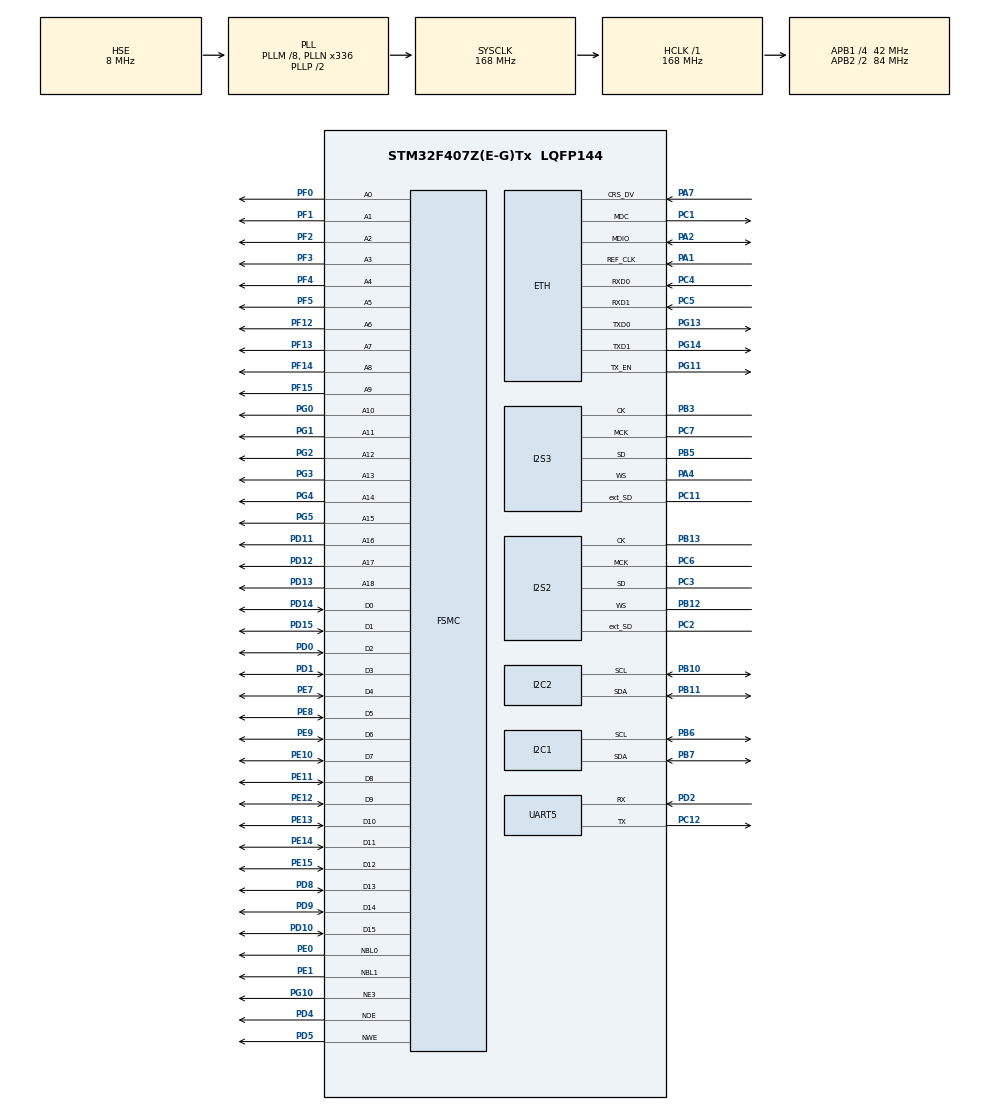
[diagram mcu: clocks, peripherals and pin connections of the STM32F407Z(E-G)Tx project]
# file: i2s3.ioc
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Dma.Request0=SPI3_TX
Dma.Request1=SPI2_TX
Dma.SPI2_TX.1.Direction=DMA_MEMORY_TO_PERIPH
Dma.SPI2_TX.1.FIFOMode=DMA_FIFOMODE_ENABLE
Dma.SPI2_TX.1.FIFOThreshold=DMA_FIFO_THRESHOLD_FULL
Dma.SPI2_TX.1.Instance=DMA1_Stream4
Dma.SPI2_TX.1.MemBurst=DMA_MBURST_SINGLE
Dma.SPI2_TX.1.MemDataAlignment=DMA_MDATAALIGN_HALFWORD
Dma.SPI2_TX.1.MemInc=DMA_MINC_ENABLE
Dma.SPI2_TX.1.Mode=DMA_NORMAL
Dma.SPI2_TX.1.PeriphBurst=DMA_PBURST_SINGLE
Dma.SPI2_TX.1.PeriphDataAlignment=DMA_PDATAALIGN_HALFWORD
Dma.SPI2_TX.1.PeriphInc=DMA_PINC_DISABLE
Dma.SPI2_TX.1.Priority=DMA_PRIORITY_LOW
Dma.SPI3_TX.0.Direction=DMA_MEMORY_TO_PERIPH
Dma.SPI3_TX.0.FIFOMode=DMA_FIFOMODE_ENABLE
Dma.SPI3_TX.0.FIFOThreshold=DMA_FIFO_THRESHOLD_FULL
Dma.SPI3_TX.0.Instance=DMA1_Stream5
Dma.SPI3_TX.0.MemBurst=DMA_MBURST_SINGLE
Dma.SPI3_TX.0.MemDataAlignment=DMA_MDATAALIGN_HALFWORD
Dma.SPI3_TX.0.MemInc=DMA_MINC_ENABLE
Dma.SPI3_TX.0.Mode=DMA_NORMAL
Dma.SPI3_TX.0.PeriphBurst=DMA_PBURST_SINGLE
Dma.SPI3_TX.0.PeriphDataAlignment=DMA_PDATAALIGN_HALFWORD
Dma.SPI3_TX.0.PeriphInc=DMA_PINC_DISABLE
Dma.SPI3_TX.0.Priority=DMA_PRIORITY_LOW
ETH.MediaInterface=ETH_MEDIA_INTERFACE_RMII
ETH.PHY_Name_RMII=DP83848_PHY_ADDRESS
FSMC.AddressSetupTime3=2
FSMC.BusTurnAroundDuration3=0
FSMC.DataSetupTime3=7
FSMC.WriteOperation3=FSMC_WRITE_OPERATION_ENABLE
I2S2.AudioFreq=I2S_AUDIOFREQ_16K
I2S2.ErrorAudioFreq=1.9 %
I2S2.FullDuplexMode=I2S_FULLDUPLEXMODE_ENABLE
I2S2.Instance=SPI$Index
I2S2.RealAudioFreq=16.304 KHz
I2S2.VirtualMode=I2S_MODE_MASTER
I2S3.AudioFreq=I2S_AUDIOFREQ_16K
I2S3.ErrorAudioFreq=1.9 %
I2S3.FullDuplexMode=I2S_FULLDUPLEXMODE_ENABLE
I2S3.Instance=SPI$Index
I2S3.RealAudioFreq=16.304 KHz
I2S3.VirtualMode=I2S_MODE_MASTER
LWIP.GATEWAY_ADDRESS=192.168.001.001
LWIP.IP_ADDRESS=192.168.001.200
LWIP.LWIP_DHCP=0
LWIP.MEMP_NUM_TCP_SEG=1000
LWIP.MEM_SIZE=970*15
LWIP.NETMASK_ADDRESS=255.255.255.000
LWIP.PBUF_POOL_BUFSIZE=970
LWIP.TCP_MSS=970
LWIP.TCP_SND_BUF=4850
LWIP.TCP_SND_QUEUELEN=1000
LWIP.TCP_WND=4850
LWIP.Version=v2.1.2_Cube
Mcu.Family=STM32F4
Mcu.Name=STM32F407Z(E-G)Tx
Mcu.Package=LQFP144
NVIC.DMA1_Stream4_IRQn=true\:2\:0\:true\:false\:true\:false\:true
NVIC.DMA1_Stream5_IRQn=true\:6\:0\:true\:false\:true\:false\:true
NVIC.ETH_IRQn=true\:2\:0\:true\:false\:true\:true\:true
NVIC.PriorityGroup=NVIC_PRIORITYGROUP_4
PA1.Mode=RMII
PA1.Signal=ETH_REF_CLK
PA2.Mode=RMII
PA2.Signal=ETH_MDIO
PA4.Mode=Full_Duplex_Master
PA4.Signal=I2S3_WS
PA7.Mode=RMII
PA7.Signal=ETH_CRS_DV
PB10.GPIO_Pu=GPIO_PULLUP
PB10.Mode=I2C
PB10.Signal=I2C2_SCL
PB11.GPIO_Pu=GPIO_PULLUP
PB11.Mode=I2C
PB11.Signal=I2C2_SDA
PB12.Mode=Full_Duplex_Master
PB12.Signal=I2S2_WS
PB13.Mode=Full_Duplex_Master
PB13.Signal=I2S2_CK
PB3.Mode=Full_Duplex_Master
PB3.Signal=I2S3_CK
PB5.Mode=Full_Duplex_Master
PB5.Signal=I2S3_SD
PB6.GPIO_Pu=GPIO_PULLUP
PB6.Mode=I2C
PB6.Signal=I2C1_SCL
PB7.GPIO_Pu=GPIO_PULLUP
PB7.Mode=I2C
PB7.Signal=I2C1_SDA
PC1.Mode=RMII
PC1.Signal=ETH_MDC
PC11.Mode=Full_Duplex_Master
PC11.Signal=I2S3_ext_SD
PC12.Mode=Asynchronous
PC12.Signal=UART5_TX
PC2.Mode=Full_Duplex_Master
PC2.Signal=I2S2_ext_SD
PC3.Mode=Full_Duplex_Master
PC3.Signal=I2S2_SD
PC4.Mode=RMII
PC4.Signal=ETH_RXD0
PC5.Mode=RMII
PC5.Signal=ETH_RXD1
PC6.Mode=Master_Clock_Activated
PC6.Signal=I2S2_MCK
PC7.Mode=Master_Clock_Activated
PC7.Signal=I2S3_MCK
PD0.Signal=FSMC_D2_DA2
PD1.Signal=FSMC_D3_DA3
PD10.Signal=FSMC_D15_DA15
PD11.Signal=FSMC_A16_CLE
PD12.Signal=FSMC_A17_ALE
PD13.Signal=FSMC_A18
PD14.Signal=FSMC_D0_DA0
PD15.Signal=FSMC_D1_DA1
PD2.Mode=Asynchronous
PD2.Signal=UART5_RX
PD4.Signal=FSMC_NOE
PD5.Signal=FSMC_NWE
PD8.Signal=FSMC_D13_DA13
PD9.Signal=FSMC_D14_DA14
PE0.Signal=FSMC_NBL0
PE1.Signal=FSMC_NBL1
PE10.Signal=FSMC_D7_DA7
PE11.Signal=FSMC_D8_DA8
PE12.Signal=FSMC_D9_DA9
PE13.Signal=FSMC_D10_DA10
PE14.Signal=FSMC_D11_DA11
PE15.Signal=FSMC_D12_DA12
PE7.Signal=FSMC_D4_DA4
PE8.Signal=FSMC_D5_DA5
PE9.Signal=FSMC_D6_DA6
PF0.Signal=FSMC_A0
PF1.Signal=FSMC_A1
PF12.Signal=FSMC_A6
PF13.Signal=FSMC_A7
PF14.Signal=FSMC_A8
PF15.Signal=FSMC_A9
PF2.Signal=FSMC_A2
PF3.Signal=FSMC_A3
PF4.Signal=FSMC_A4
PF5.Signal=FSMC_A5
PG0.Signal=FSMC_A10
PG1.Signal=FSMC_A11
PG10.Mode=NorPsramChipSelect3_3
PG10.Signal=FSMC_NE3
PG11.Mode=RMII
PG11.Signal=ETH_TX_EN
PG13.Mode=RMII
PG13.Signal=ETH_TXD0
PG14.Mode=RMII
PG14.Signal=ETH_TXD1
PG2.Signal=FSMC_A12
PG3.Signal=FSMC_A13
PG4.Signal=FSMC_A14
PG5.Signal=FSMC_A15
PH0-OSC_IN.Mode=HSE-External-Oscillator
PH0-OSC_IN.Signal=RCC_OSC_IN
PH1-OSC_OUT.Mode=HSE-External-Oscillator
PH1-OSC_OUT.Signal=RCC_OSC_OUT
ProjectManager.HeapSize=0x800
ProjectManager.StackSize=0x800
ProjectManager.TargetToolchain=STM32CubeIDE
RCC.48MHZClocksFreq_Value=48000000
RCC.AHBFreq_Value=168000000
RCC.APB1CLKDivider=RCC_HCLK_DIV4
RCC.APB1Freq_Value=42000000
RCC.APB1TimFreq_Value=84000000
RCC.APB2CLKDivider=RCC_HCLK_DIV2
RCC.APB2Freq_Value=84000000
RCC.APB2TimFreq_Value=168000000
RCC.CortexFreq_Value=168000000
RCC.HCLKFreq_Value=168000000
RCC.HSE_VALUE=8000000
RCC.HSI_VALUE=16000000
RCC.LSE_VALUE=32768
RCC.PLLM=8
RCC.PLLN=336
RCC.PLLQ=7
RCC.PLLSourceVirtual=RCC_PLLSOURCE_HSE
RCC.SYSCLKFreq_VALUE=168000000
RCC.SYSCLKSource=RCC_SYSCLKSOURCE_PLLCLK
RCC.VCOOutputFreq_Value=336000000
SH.FSMC_A0.0=FSMC_A0,19b-a3
SH.FSMC_A1.0=FSMC_A1,19b-a3
SH.FSMC_A10.0=FSMC_A10,19b-a3
SH.FSMC_A11.0=FSMC_A11,19b-a3
SH.FSMC_A12.0=FSMC_A12,19b-a3
SH.FSMC_A13.0=FSMC_A13,19b-a3
SH.FSMC_A14.0=FSMC_A14,19b-a3
SH.FSMC_A15.0=FSMC_A15,19b-a3
SH.FSMC_A16_CLE.0=FSMC_A16,19b-a3
SH.FSMC_A17_ALE.0=FSMC_A17,19b-a3
SH.FSMC_A18.0=FSMC_A18,19b-a3
SH.FSMC_A2.0=FSMC_A2,19b-a3
SH.FSMC_A3.0=FSMC_A3,19b-a3
SH.FSMC_A4.0=FSMC_A4,19b-a3
SH.FSMC_A5.0=FSMC_A5,19b-a3
SH.FSMC_A6.0=FSMC_A6,19b-a3
SH.FSMC_A7.0=FSMC_A7,19b-a3
SH.FSMC_A8.0=FSMC_A8,19b-a3
SH.FSMC_A9.0=FSMC_A9,19b-a3
SH.FSMC_D0_DA0.0=FSMC_D0,16b-d3
SH.FSMC_D10_DA10.0=FSMC_D10,16b-d3
SH.FSMC_D11_DA11.0=FSMC_D11,16b-d3
SH.FSMC_D12_DA12.0=FSMC_D12,16b-d3
SH.FSMC_D13_DA13.0=FSMC_D13,16b-d3
SH.FSMC_D14_DA14.0=FSMC_D14,16b-d3
SH.FSMC_D15_DA15.0=FSMC_D15,16b-d3
SH.FSMC_D1_DA1.0=FSMC_D1,16b-d3
SH.FSMC_D2_DA2.0=FSMC_D2,16b-d3
SH.FSMC_D3_DA3.0=FSMC_D3,16b-d3
SH.FSMC_D4_DA4.0=FSMC_D4,16b-d3
SH.FSMC_D5_DA5.0=FSMC_D5,16b-d3
SH.FSMC_D6_DA6.0=FSMC_D6,16b-d3
SH.FSMC_D7_DA7.0=FSMC_D7,16b-d3
SH.FSMC_D8_DA8.0=FSMC_D8,16b-d3
SH.FSMC_D9_DA9.0=FSMC_D9,16b-d3
SH.FSMC_NBL0.0=FSMC_NBL0,2ByteEnable3
SH.FSMC_NBL1.0=FSMC_NBL1,2ByteEnable3
SH.FSMC_NOE.0=FSMC_NOE,Sram3
SH.FSMC_NWE.0=FSMC_NWE,Sram3
UART5.VirtualMode=Asynchronous
VP_LWIP_VS_Enabled.Mode=Enabled
board=custom

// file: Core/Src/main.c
/* USER CODE BEGIN Header */
/**
  ******************************************************************************
  * @file           : main.c
  * @brief          : Main program body
  ******************************************************************************
  * @attention
  *
  * Copyright (c) 2025 STMicroelectronics.
  * All rights reserved.
  *
  * This software is licensed under terms that can be found in the LICENSE file
  * in the root directory of this software component.
  * If no LICENSE file comes with this software, it is provided AS-IS.
  *
  ******************************************************************************
  */
/* USER CODE END Header */
#include "main.h"
#include "lwip.h"

/* USER CODE BEGIN Includes */
#include "audio_player.h"
#include "tcpClientRAW.h"
#include "i2s.h"
/* USER CODE END Includes */

I2C_HandleTypeDef hi2c1;
I2C_HandleTypeDef hi2c2;

I2S_HandleTypeDef hi2s2;
I2S_HandleTypeDef hi2s3;
DMA_HandleTypeDef hdma_spi2_tx;
DMA_HandleTypeDef hdma_spi3_tx;

UART_HandleTypeDef huart5;

SRAM_HandleTypeDef hsram3;

void SystemClock_Config(void);
void PeriphCommonClock_Config(void);
static void MX_GPIO_Init(void);
static void MX_DMA_Init(void);
static void MX_I2S3_Init(void);
static void MX_I2C1_Init(void);
static void MX_I2C2_Init(void);
static void MX_I2S2_Init(void);
static void MX_UART5_Init(void);
static void MX_FSMC_Init(void);
/* USER CODE BEGIN PFP */
#define BUFFSIZE  970
/* USER CODE END PFP */

/* USER CODE BEGIN 0 */
#include <string.h>
#include <stdio.h>

#ifdef __GNUC__
  /* With GCC, small printf (option LD Linker->Libraries->Small printf
     set to 'Yes') calls __io_putchar() */
int __io_putchar(int ch)
#else
int fputc(int ch, FILE *f)
#endif /* __GNUC__ */
{
  /* Place your implementation of fputc here */
  /* e.g. write a character to the UART3 and Loop until the end of transmission */
  HAL_UART_Transmit(&huart5, (uint8_t *)&ch, 1, HAL_MAX_DELAY);
  return ch;
}

char      UsbDiskPath[4] = {0};                         /* USB Host logical drive path */
uint32_t  byteswritten, bytesread;                      /* File write/read counts */
char      file_name[] = "recorder.wav";                     /* File name */
char      file_name2[] = "queen.wav";                     /* File name */

uint8_t wavsram[11640];
//uint8_t wavsram[1024000] __attribute__((section(".sram")));

//extern uint8_t wavsram[1024000];

/* USER CODE END 0 */

int main(void)
{

  /* MCU Configuration--------------------------------------------------------*/

  /* Reset of all peripherals, Initializes the Flash interface and the Systick. */
  HAL_Init();

  /* Configure the system clock */
  SystemClock_Config();

/* Configure the peripherals common clocks */
  PeriphCommonClock_Config();

  /* Initialize all configured peripherals */
  MX_GPIO_Init();
  MX_DMA_Init();
  MX_I2S3_Init();
  MX_I2C1_Init();
  MX_I2C2_Init();
  MX_I2S2_Init();
  MX_UART5_Init();
  MX_LWIP_Init();
  MX_FSMC_Init();
  /* USER CODE BEGIN 2 */
  Audio_Player_Init(&hi2c2);

  Audio_Player_Init(&hi2c1);
  	HAL_Delay(1000);
	WM8978_HPvol_Set(40, 40);	//耳机音量设置
	WM8978_SPKvol_Set(50);	//喇叭音量设置
  	WM8978_ADDA_Cfg(0, 1);		//�????????????????????????????????????????启ADC
  	WM8978_Input_Cfg(1, 1, 0);	//�????????????????????????????????????????启输入�?�道(MIC&LINE IN)
  	WM8978_Output_Cfg(0, 1);		//�????????????????????????????????????????启BYPASS输出
  	WM8978_MIC_Gain(46);		//MIC增益设置
  	WM8978_I2S_Cfg(2, 0);//
  //ETX_MSC_ProcessUsbDevice();

//  res = f_mount( &UsbDiskFatFs, (TCHAR const*)UsbDiskPath, 0 );
//  printf("mount %d\n",res);
//  res = f_open( &file, file_name, FA_READ );
//  f_lseek(&file,44);
//  printf("open %d\n",res);
//  res = f_open( &file2, file_name2, FA_READ );
//  f_lseek(&file2,44);
//  printf("open %d\n",res);
  tcp_client_init();
  //Audio_Player_Start();

  /* USER CODE END 2 */

  /* Infinite loop */
  while (1)
  {

    /* USER CODE BEGIN 3 */
	  MX_LWIP_Process();

	 // HAL_Delay(50000);
  }
  /* USER CODE END 3 */
}

void SystemClock_Config(void)
{
  RCC_OscInitTypeDef RCC_OscInitStruct = {0};
  RCC_ClkInitTypeDef RCC_ClkInitStruct = {0};

  /** Configure the main internal regulator output voltage
  */
  __HAL_RCC_PWR_CLK_ENABLE();
  __HAL_PWR_VOLTAGESCALING_CONFIG(PWR_REGULATOR_VOLTAGE_SCALE1);
  /** Initializes the RCC Oscillators according to the specified parameters
  * in the RCC_OscInitTypeDef structure.
  */
  RCC_OscInitStruct.OscillatorType = RCC_OSCILLATORTYPE_HSE;
  RCC_OscInitStruct.HSEState = RCC_HSE_ON;
  RCC_OscInitStruct.PLL.PLLState = RCC_PLL_ON;
  RCC_OscInitStruct.PLL.PLLSource = RCC_PLLSOURCE_HSE;
  RCC_OscInitStruct.PLL.PLLM = 8;
  RCC_OscInitStruct.PLL.PLLN = 336;
  RCC_OscInitStruct.PLL.PLLP = RCC_PLLP_DIV2;
  RCC_OscInitStruct.PLL.PLLQ = 7;
  if (HAL_RCC_OscConfig(&RCC_OscInitStruct) != HAL_OK)
  {
    Error_Handler();
  }
  /** Initializes the CPU, AHB and APB buses clocks
  */
  RCC_ClkInitStruct.ClockType = RCC_CLOCKTYPE_HCLK|RCC_CLOCKTYPE_SYSCLK
                              |RCC_CLOCKTYPE_PCLK1|RCC_CLOCKTYPE_PCLK2;
  RCC_ClkInitStruct.SYSCLKSource = RCC_SYSCLKSOURCE_PLLCLK;
  RCC_ClkInitStruct.AHBCLKDivider = RCC_SYSCLK_DIV1;
  RCC_ClkInitStruct.APB1CLKDivider = RCC_HCLK_DIV4;
  RCC_ClkInitStruct.APB2CLKDivider = RCC_HCLK_DIV2;

  if (HAL_RCC_ClockConfig(&RCC_ClkInitStruct, FLASH_LATENCY_5) != HAL_OK)
  {
    Error_Handler();
  }
}

void PeriphCommonClock_Config(void)
{
  RCC_PeriphCLKInitTypeDef PeriphClkInitStruct = {0};

  /** Initializes the peripherals clock
  */
  PeriphClkInitStruct.PeriphClockSelection = RCC_PERIPHCLK_I2S;
  PeriphClkInitStruct.PLLI2S.PLLI2SN = 192;
  PeriphClkInitStruct.PLLI2S.PLLI2SR = 2;
  if (HAL_RCCEx_PeriphCLKConfig(&PeriphClkInitStruct) != HAL_OK)
  {
    Error_Handler();
  }
}

static void MX_I2C1_Init(void)
{

  hi2c1.Instance = I2C1;
  hi2c1.Init.ClockSpeed = 100000;
  hi2c1.Init.DutyCycle = I2C_DUTYCYCLE_2;
  hi2c1.Init.OwnAddress1 = 0;
  hi2c1.Init.AddressingMode = I2C_ADDRESSINGMODE_7BIT;
  hi2c1.Init.DualAddressMode = I2C_DUALADDRESS_DISABLE;
  hi2c1.Init.OwnAddress2 = 0;
  hi2c1.Init.GeneralCallMode = I2C_GENERALCALL_DISABLE;
  hi2c1.Init.NoStretchMode = I2C_NOSTRETCH_DISABLE;
  if (HAL_I2C_Init(&hi2c1) != HAL_OK)
  {
    Error_Handler();
  }

}

static void MX_I2C2_Init(void)
{

  hi2c2.Instance = I2C2;
  hi2c2.Init.ClockSpeed = 100000;
  hi2c2.Init.DutyCycle = I2C_DUTYCYCLE_2;
  hi2c2.Init.OwnAddress1 = 0;
  hi2c2.Init.AddressingMode = I2C_ADDRESSINGMODE_7BIT;
  hi2c2.Init.DualAddressMode = I2C_DUALADDRESS_DISABLE;
  hi2c2.Init.OwnAddress2 = 0;
  hi2c2.Init.GeneralCallMode = I2C_GENERALCALL_DISABLE;
  hi2c2.Init.NoStretchMode = I2C_NOSTRETCH_DISABLE;
  if (HAL_I2C_Init(&hi2c2) != HAL_OK)
  {
    Error_Handler();
  }

}

static void MX_I2S2_Init(void)
{

  hi2s2.Instance = SPI2;
  hi2s2.Init.Mode = I2S_MODE_MASTER_TX;
  hi2s2.Init.Standard = I2S_STANDARD_PHILIPS;
  hi2s2.Init.DataFormat = I2S_DATAFORMAT_16B;
  hi2s2.Init.MCLKOutput = I2S_MCLKOUTPUT_ENABLE;
  hi2s2.Init.AudioFreq = I2S_AUDIOFREQ_16K;
  hi2s2.Init.CPOL = I2S_CPOL_LOW;
  hi2s2.Init.ClockSource = I2S_CLOCK_PLL;
  hi2s2.Init.FullDuplexMode = I2S_FULLDUPLEXMODE_ENABLE;
  if (HAL_I2S_Init(&hi2s2) != HAL_OK)
  {
    Error_Handler();
  }

}

static void MX_I2S3_Init(void)
{

  hi2s3.Instance = SPI3;
  hi2s3.Init.Mode = I2S_MODE_MASTER_TX;
  hi2s3.Init.Standard = I2S_STANDARD_PHILIPS;
  hi2s3.Init.DataFormat = I2S_DATAFORMAT_16B;
  hi2s3.Init.MCLKOutput = I2S_MCLKOUTPUT_ENABLE;
  hi2s3.Init.AudioFreq = I2S_AUDIOFREQ_16K;
  hi2s3.Init.CPOL = I2S_CPOL_LOW;
  hi2s3.Init.ClockSource = I2S_CLOCK_PLL;
  hi2s3.Init.FullDuplexMode = I2S_FULLDUPLEXMODE_ENABLE;
  if (HAL_I2S_Init(&hi2s3) != HAL_OK)
  {
    Error_Handler();
  }

}

static void MX_UART5_Init(void)
{

  huart5.Instance = UART5;
  huart5.Init.BaudRate = 115200;
  huart5.Init.WordLength = UART_WORDLENGTH_8B;
  huart5.Init.StopBits = UART_STOPBITS_1;
  huart5.Init.Parity = UART_PARITY_NONE;
  huart5.Init.Mode = UART_MODE_TX_RX;
  huart5.Init.HwFlowCtl = UART_HWCONTROL_NONE;
  huart5.Init.OverSampling = UART_OVERSAMPLING_16;
  if (HAL_UART_Init(&huart5) != HAL_OK)
  {
    Error_Handler();
  }

}

static void MX_DMA_Init(void)
{

  /* DMA controller clock enable */
  __HAL_RCC_DMA1_CLK_ENABLE();

  /* DMA interrupt init */
  /* DMA1_Stream4_IRQn interrupt configuration */
  HAL_NVIC_SetPriority(DMA1_Stream4_IRQn, 2, 0);
  HAL_NVIC_EnableIRQ(DMA1_Stream4_IRQn);
  /* DMA1_Stream5_IRQn interrupt configuration */
  HAL_NVIC_SetPriority(DMA1_Stream5_IRQn, 6, 0);
  HAL_NVIC_EnableIRQ(DMA1_Stream5_IRQn);

}

static void MX_GPIO_Init(void)
{

  /* GPIO Ports Clock Enable */
  __HAL_RCC_GPIOF_CLK_ENABLE();
  __HAL_RCC_GPIOH_CLK_ENABLE();
  __HAL_RCC_GPIOC_CLK_ENABLE();
  __HAL_RCC_GPIOA_CLK_ENABLE();
  __HAL_RCC_GPIOG_CLK_ENABLE();
  __HAL_RCC_GPIOE_CLK_ENABLE();
  __HAL_RCC_GPIOB_CLK_ENABLE();
  __HAL_RCC_GPIOD_CLK_ENABLE();

}

/* FSMC initialization function */
static void MX_FSMC_Init(void)
{

  FSMC_NORSRAM_TimingTypeDef Timing = {0};

  /** Perform the SRAM3 memory initialization sequence
  */
  hsram3.Instance = FSMC_NORSRAM_DEVICE;
  hsram3.Extended = FSMC_NORSRAM_EXTENDED_DEVICE;
  /* hsram3.Init */
  hsram3.Init.NSBank = FSMC_NORSRAM_BANK3;
  hsram3.Init.DataAddressMux = FSMC_DATA_ADDRESS_MUX_DISABLE;
  hsram3.Init.MemoryType = FSMC_MEMORY_TYPE_SRAM;
  hsram3.Init.MemoryDataWidth = FSMC_NORSRAM_MEM_BUS_WIDTH_16;
  hsram3.Init.BurstAccessMode = FSMC_BURST_ACCESS_MODE_DISABLE;
  hsram3.Init.WaitSignalPolarity = FSMC_WAIT_SIGNAL_POLARITY_LOW;
  hsram3.Init.WrapMode = FSMC_WRAP_MODE_DISABLE;
  hsram3.Init.WaitSignalActive = FSMC_WAIT_TIMING_BEFORE_WS;
  hsram3.Init.WriteOperation = FSMC_WRITE_OPERATION_ENABLE;
  hsram3.Init.WaitSignal = FSMC_WAIT_SIGNAL_DISABLE;
  hsram3.Init.ExtendedMode = FSMC_EXTENDED_MODE_DISABLE;
  hsram3.Init.AsynchronousWait = FSMC_ASYNCHRONOUS_WAIT_DISABLE;
  hsram3.Init.WriteBurst = FSMC_WRITE_BURST_DISABLE;
  hsram3.Init.PageSize = FSMC_PAGE_SIZE_NONE;
  /* Timing */
  Timing.AddressSetupTime =3;
  Timing.AddressHoldTime = 15;
  Timing.DataSetupTime = 8;
  Timing.BusTurnAroundDuration = 0;
  Timing.CLKDivision = 16;
  Timing.DataLatency = 17;
  Timing.AccessMode = FSMC_ACCESS_MODE_A;
  /* ExtTiming */

  if (HAL_SRAM_Init(&hsram3, &Timing, NULL) != HAL_OK)
  {
    Error_Handler( );
  }

}

void Error_Handler(void)
{
  __disable_irq();
  while (1)
  {
  }
}
